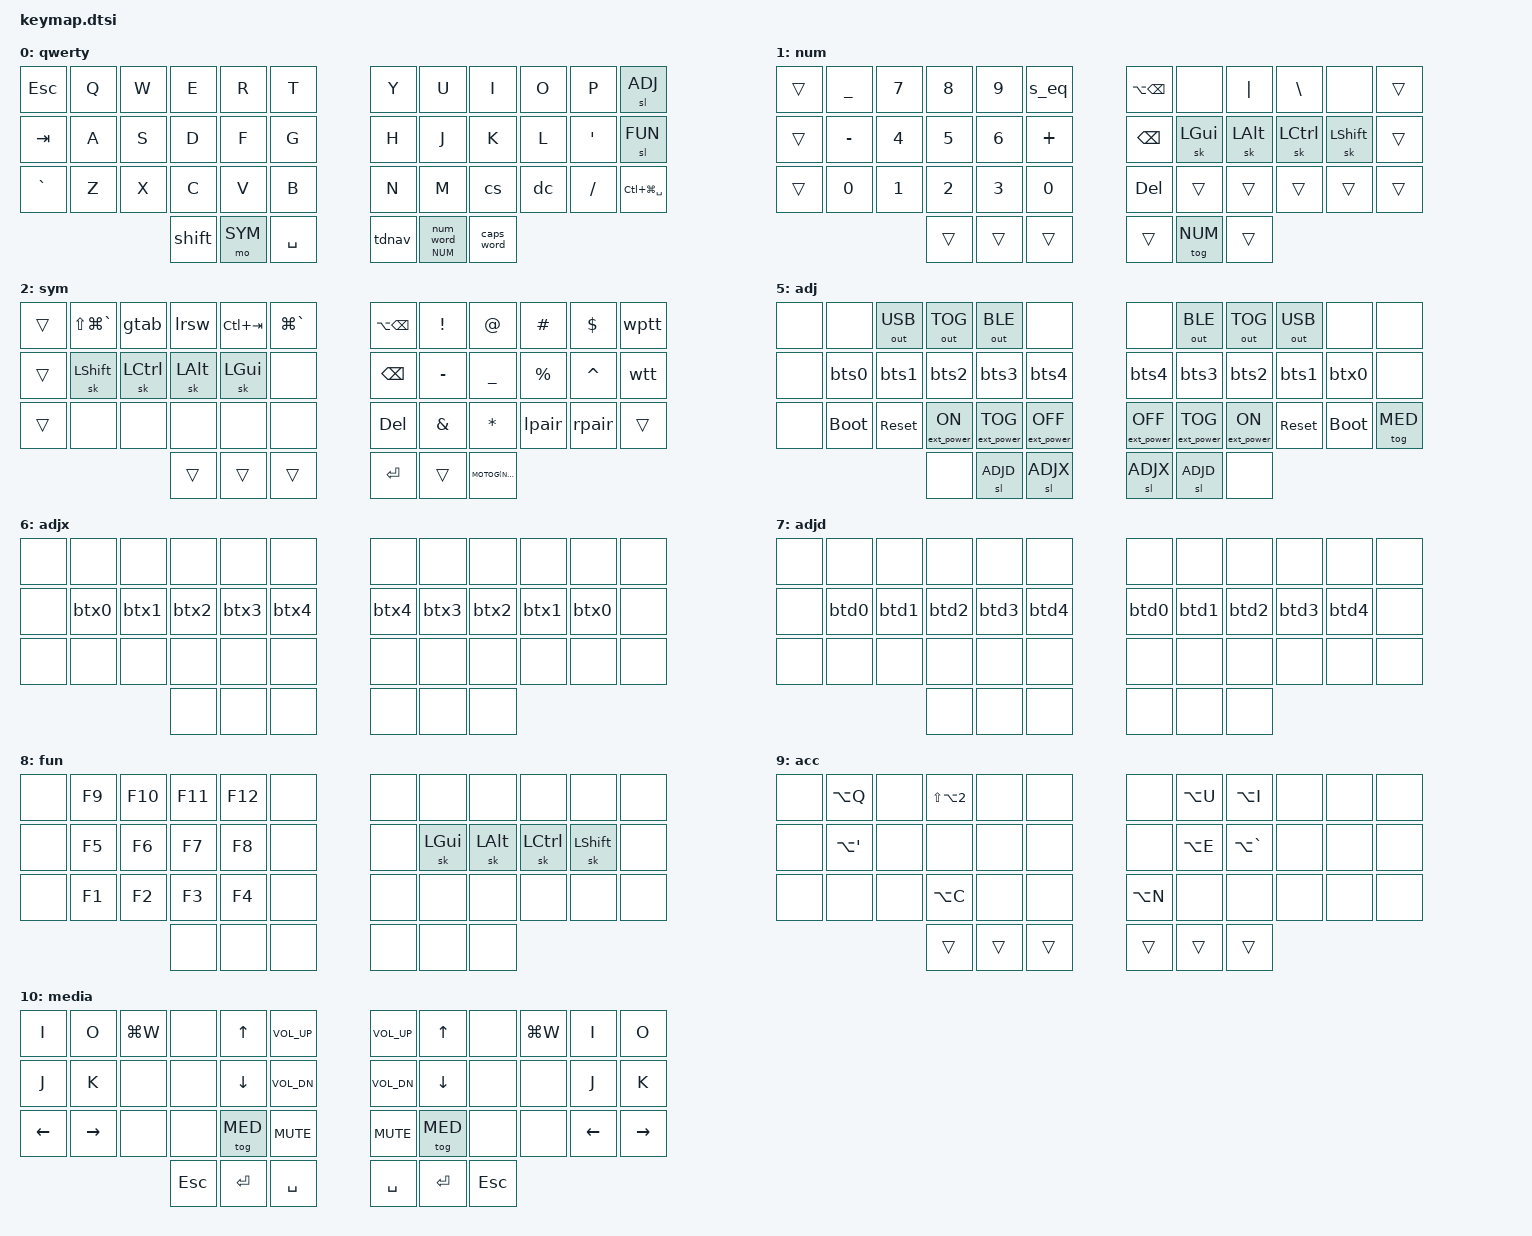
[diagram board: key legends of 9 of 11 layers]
#include <behaviors.dtsi>
#include <dt-bindings/zmk/keys.h>
#include <dt-bindings/zmk/bt.h>
#include <dt-bindings/zmk/outputs.h>
#include <dt-bindings/zmk/ext_power.h>

#define ZMK_MOUSE_DEFAULT_MOVE_VAL 1500  // 600
#define ZMK_MOUSE_DEFAULT_SCRL_VAL 20    // 10

#include <dt-bindings/zmk/mouse.h>

&mmv {
    acceleration-exponent = <1>;      // 1
    time-to-max-speed-ms = <500>;     // 300
    delay-ms = <0>;                   // 0
};

&msc {
    acceleration-exponent = <1>;      // 0
    time-to-max-speed-ms = <40>;      // 300
    delay-ms = <0>;                   // 0
};

#define QWE 0

#define NUM 1
#define SYM 2
#define NAV 3
#define MOU 4

#define ADJ 5
#define ADJX 6
#define ADJD 7

#define FUN 8
#define ACC 9
#define MED 10

#define ___ &none

// see https://zmk.dev/docs/behaviors/hold-tap#example-use-cases
#define MOTOG(layer) &mo_tog layer layer   // Macro to apply momentary-layer-on-hold/toggle-layer-on-tap to a specific layer

#define MOD_MORPH(NAME, MODS, ...) NAME: NAME { mods = <MODS>; bindings = __VA_ARGS__; #binding-cells = <0>; compatible = "zmk,behavior-mod-morph"; };
#define MACRO(NAME, ...) NAME: NAME { bindings = __VA_ARGS__; #binding-cells = <0>; compatible = "zmk,behavior-macro"; };

&sk {
    quick-release;
};

&caps_word {
    continue-list = <BACKSPACE DELETE UNDERSCORE MINUS>;
};

&num_word {
    layers = <NUM>;
    continue-list = <BACKSPACE DELETE DOT COMMA MINUS>;
};

/ {
    combos {
        compatible = "zmk,combos";
        combo_acc {
            timeout-ms = <50>;
            key-positions = <15 16>;
            layers = <QWE>;
            bindings = <&sl ACC>;
        };
        combo_adj {
            timeout-ms = <50>;
            key-positions = <0 5>;
            layers = <SYM>;
            bindings = <&sl ADJ>;
        };
        combo_bt_clr {
            timeout-ms = <50>;
            key-positions = <1 5>;
            layers = <ADJ>;
            bindings = <&bt BT_CLR>;
        };
/*
  0     1   2   3   4   5     6   7   8   9  10    11
 12    13  14  15  16  17    18  19  20  21  22    23
 24    25  26  27  28  29    30  31  32  33  34    35
               36  37  38    39  40  41
*/
    };
    behaviors {
        tdnav: tdnav {
            compatible = "zmk,behavior-tap-dance";
            #binding-cells = <0>;
            tapping-term-ms = <200>;
            bindings = <&mo NAV>, <&mo MOU>;
        };
       mo_tog: mo_tog {
            compatible = "zmk,behavior-hold-tap";
            #binding-cells = <2>;
            flavor = "hold-preferred";
            tapping-term-ms = <200>;
            bindings = <&mo>, <&tog>;
        };
        shift: shift {
            compatible = "zmk,behavior-mod-morph";
            #binding-cells = <0>;
            bindings = <&sk RSHFT>, <&caps_word>;
            mods = <MOD_RSFT>;
        };
        num: num {
            compatible = "zmk,behavior-hold-tap";
            #binding-cells = <2>;
            flavor = "tap-preferred";
            tapping-term-ms = <200>;
            bindings = <&mo>, <&num_word>;
        };
        cs: cs {
            compatible = "zmk,behavior-mod-morph";
            #binding-cells = <0>;
            bindings = <&kp COMMA>, <&kp SEMICOLON>;
            mods = <MOD_RSFT>;
        };
        dc: dc {
            compatible = "zmk,behavior-mod-morph";
            #binding-cells = <0>;
            bindings = <&kp DOT>, <&kp COLON>;
            mods = <MOD_RSFT>;
        };
        gtab: gtab {
            compatible = "zmk,behavior-tri-state";
            #binding-cells = <0>;
            bindings = <&kt LGUI>, <&kp TAB>, <&kt LGUI>;
            ignored-key-positions = <3 32>;
        };
        lrsw: lrsw {
            compatible = "zmk,behavior-mod-morph";
            #binding-cells = <0>;
            bindings = <&kp LS(LC(TAB))>, <&kp LS(TAB)>;
            mods = <MOD_LGUI>;
            keep-mods = <MOD_LGUI>;
        };
        rrsw: rrsw {
            compatible = "zmk,behavior-mod-morph";
            #binding-cells = <0>;
            bindings = <&kp LC(TAB)>, <&kp LS(TAB)>;
            mods = <MOD_LGUI>;
            keep-mods = <MOD_LGUI>;
        };

        MOD_MORPH(lpair, MOD_LCTL, <&lpa_2  >, <&kp LT  >)
        MOD_MORPH(lpa_2, MOD_LALT, <&lpa_3  >, <&kp LBKT>)
        MOD_MORPH(lpa_3, MOD_LGUI, <&kp LPAR>, <&kp LBRC>)
        MOD_MORPH(rpair, MOD_LCTL, <&rpa_2  >, <&kp GT  >)
        MOD_MORPH(rpa_2, MOD_LALT, <&rpa_3  >, <&kp RBKT>)
        MOD_MORPH(rpa_3, MOD_LGUI, <&kp RPAR>, <&kp RBRC>)
 
        MOD_MORPH(s_eq, MOD_LGUI, <&s_e2    >, <&col_eq >)
        MOD_MORPH(s_e2, MOD_LALT, <&s_e3    >, <&excl_eq>)
        MOD_MORPH(s_e3, MOD_LCTL, <&kp EQUAL>, <&eq_eq  >)

        etabs: etabs {
            compatible = "zmk,behavior-sensor-rotate";
            #sensor-binding-cells = <0>;
            bindings = <&kp LC(TAB) &kp LS(LC(TAB))>;
        };
        egtab: egtab {
            compatible = "zmk,behavior-tri-state";
            #binding-cells = <0>;
            bindings = <&kt LGUI>, <&kp TAB>, <&kt LGUI>;
        };
        ewins: ewins {
            compatible = "zmk,behavior-sensor-rotate";
            #sensor-binding-cells = <0>;
            bindings = <&egtab &kp LS(TAB)>;
        };
    };
    macros {
        MACRO(kill_word, <&macro_tap &kp ESC   &kp D>)
        MACRO(tmux_prev, <&macro_tap &kp LC(Q) &kp P>)
        MACRO(tmux_next, <&macro_tap &kp LC(Q) &kp N>)

        MACRO( col_eq, <&macro_tap &kp COLON &kp EQUAL>)
        MACRO(excl_eq, <&macro_tap &kp EXCL  &kp EQUAL>)
        MACRO(  eq_eq, <&macro_tap &kp EQUAL &kp EQUAL>)

        MACRO(wptt, <&bt BT_SEL 3>, <&macro_press &kp SPACE>, <&macro_pause_for_release>, <&macro_release &kp SPACE>, <&macro_tap>, <&bt BT_SEL 4>)
        MACRO(wtt, <&bt BT_SEL 3>, <&macro_tap &kp SPACE>, <&bt BT_SEL 4>)

        MACRO(bts0, <&bt BT_SEL 0>)
        MACRO(bts1, <&bt BT_SEL 1>)
        MACRO(bts2, <&bt BT_SEL 2>)
        MACRO(bts3, <&bt BT_SEL 3>)
        MACRO(bts4, <&bt BT_SEL 4>)

        MACRO(btd0, <&bt BT_DISC 0>)
        MACRO(btd1, <&bt BT_DISC 1>)
        MACRO(btd2, <&bt BT_DISC 2>)
        MACRO(btd3, <&bt BT_DISC 3>)
        MACRO(btd4, <&bt BT_DISC 4>)

        MACRO(btx0, <&bt BT_SEL 0>, <&bt BT_DISC 1>, <&bt BT_DISC 2>, <&bt BT_DISC 3>, <&bt BT_DISC 4>)
        MACRO(btx1, <&bt BT_SEL 1>, <&bt BT_DISC 0>, <&bt BT_DISC 2>, <&bt BT_DISC 3>, <&bt BT_DISC 4>)
        MACRO(btx2, <&bt BT_SEL 2>, <&bt BT_DISC 0>, <&bt BT_DISC 1>, <&bt BT_DISC 3>, <&bt BT_DISC 4>)
        MACRO(btx3, <&bt BT_SEL 3>, <&bt BT_DISC 0>, <&bt BT_DISC 1>, <&bt BT_DISC 2>, <&bt BT_DISC 4>)
        MACRO(btx4, <&bt BT_SEL 4>, <&bt BT_DISC 0>, <&bt BT_DISC 1>, <&bt BT_DISC 2>, <&bt BT_DISC 3>)
    };
    keymap {
        compatible = "zmk,keymap";

        qwerty {
            display-name = "qwerty";
            bindings = <
&kp ESC          &kp Q &kp W &kp  E &kp   R &kp     T        &kp   Y &kp      U &kp      I &kp O &kp    P        &sl         ADJ
&kp TAB          &kp A &kp S &kp  D &kp   F &kp     G        &kp   H &kp      J &kp      K &kp L &kp  SQT        &sl         FUN
&kp GRAVE        &kp Z &kp X &kp  C &kp   V &kp     B        &kp   N &kp      M &cs        &dc   &kp FSLH        &kp LC(LG(SPACE))
                             &shift &mo SYM &kp SPACE        &tdnav  &num NUM 0 &caps_word
            >; sensor-bindings = <
                                               &etabs           &ewins
            >;
        };
        num {
            display-name = "num";
            bindings = <
&trans        &kp UNDER &kp N7 &kp N8 &kp N9 &s_eq            &kp LA(BKSP) ___      &kp PIPE &kp  BSLH ___              &trans  
&trans        &kp MINUS &kp N4 &kp N5 &kp N6 &kp PLUS         &kp    BKSP  &sk LGUI &sk LALT &sk LCTRL &sk LSHFT        &trans  
&trans        &kp    N0 &kp N1 &kp N2 &kp N3 &kp   N0         &kp     DEL  &trans   &trans   &trans    &trans           &trans  
                               &trans &trans &trans           &trans       &tog NUM &trans
            >;
        };
        sym {
            display-name = "sym";
            bindings = <
&trans          &kp LS(LG(GRAVE)) &gtab     &lrsw    &kp LC(TAB) &kp LG(GRAVE)        &kp LA(BKSP) &kp  EXCL &kp    AT &kp  HASH &kp  DLLR        &wptt
&trans          &sk       LSHFT   &sk LCTRL &sk LALT &sk   LGUI  ___                  &kp    BKSP  &kp MINUS &kp UNDER &kp PRCNT &kp CARET        &wtt
&trans          ___               ___       ___      ___         ___                  &kp     DEL  &kp  AMPS &kp  STAR &lpair    &rpair           &trans
                                            &trans    &trans     &trans               &kp     RET  &trans    MOTOG(NAV)
            >;
        };
        nav {
            display-name = "nav";
            bindings = <
&trans        ___        &kp   HOME &kp   UP  &kp   END &kp PG_UP        &kp LC(LA(UP))   &kp LC(LA(LG(LEFT))) &kp LC(LA(LG(RIGHT))) &kp LC(W) &kill_word        &trans
&trans        ___        &kp   LEFT &kp DOWN  &kp RIGHT &kp PG_DN        &kp LC(LA(LEFT)) &kp   LC(LA(RIGHT))  &kp    LC(LA(RET))    &kp LC(R) &kp  LC(Q)        &trans
&trans        &tmux_prev &tmux_next &kp LA(B) &kp LA(F) ___              &kp LC(LA(DOWN)) &sk          LGUI    &sk          LALT     &sk LCTRL &sk  LSHFT        &trans
                                    &trans     &trans   &shift           &trans           &trans               &tog    NAV
            >;
        };
        mou {
            display-name = "mouse";
            bindings = <
&trans        ___      &msc SCRL_LEFT &mmv MOVE_UP   &msc SCRL_RIGHT &msc SCRL_UP          &kp LC(LA(UP))   &kp LC(LA(LG(LEFT))) &kp LC(LA(LG(RIGHT))) &kp LC(W) &kill_word        &trans
&trans        ___      &mmv MOVE_LEFT &mmv MOVE_DOWN &mmv MOVE_RIGHT &msc SCRL_DOWN        &kp LC(LA(LEFT)) &kp   LC(LA(RIGHT))  &kp    LC(LA(RET))    &kp LC(R) &kp  LC(Q)        &trans
&trans        &mkp MB4 &mkp LCLK      &mkp MCLK      &mkp RCLK       &mkp MB5              &kp LC(LA(DOWN)) &sk          LGUI    &sk          LALT     &sk LCTRL &sk  LSHFT        &trans
                                      &mkp LCLK      &mkp MCLK       &mkp RCLK             &trans           &trans               &tog    NAV
            >;
        };
        adjust {
            display-name = "adj";
            bindings = <
___        ___         &out OUT_USB &out     OUT_TOG &out      OUT_BLE ___                      ___               &out      OUT_BLE &out     OUT_TOG &out OUT_USB ___                ___
___        &bts0       &bts1        &bts2            &bts3             &bts4                    &bts4             &bts3             &bts2            &bts1        &btx0              ___
___        &bootloader &sys_reset   &ext_power EP_ON &ext_power EP_TOG &ext_power EP_OFF        &ext_power EP_OFF &ext_power EP_TOG &ext_power EP_ON &sys_reset   &bootloader        &tog MED
                                    ___              &sl          ADJD &sl          ADJX        &sl          ADJX &sl          ADJD ___
            >;
        };
        adjust_x {
            display-name = "adjx";
            bindings = <
___        ___   ___   ___   ___   ___          ___   ___   ___   ___   ___          ___
___        &btx0 &btx1 &btx2 &btx3 &btx4        &btx4 &btx3 &btx2 &btx1 &btx0        ___
___        ___   ___   ___   ___   ___          ___   ___   ___   ___   ___          ___
                       ___   ___   ___          ___   ___   ___
            >;
        };
        adjust_d {
            display-name = "adjd";
            bindings = <
___        ___   ___   ___   ___   ___          ___   ___   ___   ___   ___          ___
___        &btd0 &btd1 &btd2 &btd3 &btd4        &btd0 &btd1 &btd2 &btd3 &btd4        ___
___        ___   ___   ___   ___   ___          ___   ___   ___   ___   ___          ___
                       ___   ___   ___          ___   ___   ___
            >;
        };
        fun {
            display-name = "fun";
            bindings = <
___        &kp F9 &kp F10 &kp F11 &kp F12 ___        ___ ___      ___      ___       ___              ___
___        &kp F5 &kp F6  &kp F7  &kp F8  ___        ___ &sk LGUI &sk LALT &sk LCTRL &sk LSHFT        ___
___        &kp F1 &kp F2  &kp F3  &kp F4  ___        ___ ___      ___      ___       ___              ___
                          ___     ___     ___        ___ ___ ___
            >;
        };
        accents {
            display-name = "acc";
            bindings = <
___          &kp LA(Q)   ___   &kp LS(LA(N2)) ___    ___          ___       &kp LA(U) &kp     LA(I) ___   ___          ___
___          &kp LA(SQT) ___   ___            ___    ___          ___       &kp LA(E) &kp LA(GRAVE) ___   ___          ___
___          ___         ___   &kp     LA(C)  ___    ___          &kp LA(N) ___       ___           ___   ___          ___
                               &trans         &trans &trans       &trans    &trans    &trans
            >;
        };
        media {
            display-name = "media";
            bindings = <
&kp    I        &kp     O &kp LG(W)  ___     &kp   UP &kp C_VOL_UP        &kp C_VOL_UP &kp   UP ___     &kp LG(W) &kp    I        &kp     O
&kp    J        &kp     K ___        ___     &kp DOWN &kp C_VOL_DN        &kp C_VOL_DN &kp DOWN ___     ___       &kp    J        &kp     K 
&kp LEFT        &kp RIGHT ___        ___     &tog MED &kp   C_MUTE        &kp   C_MUTE &tog MED ___     ___       &kp LEFT        &kp RIGHT 
                                     &kp ESC &kp  RET &kp    SPACE        &kp    SPACE &kp  RET &kp ESC
            >;
        };
    };
};
